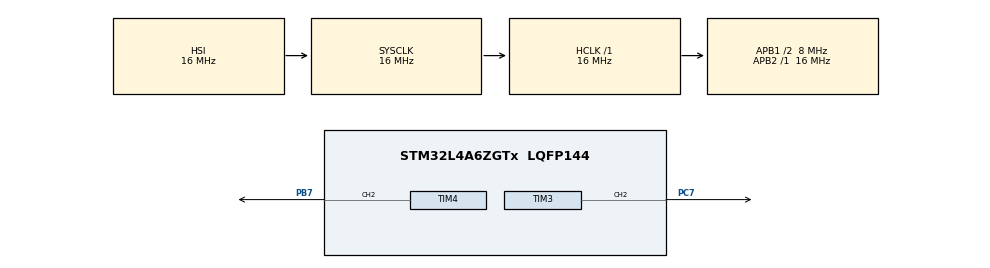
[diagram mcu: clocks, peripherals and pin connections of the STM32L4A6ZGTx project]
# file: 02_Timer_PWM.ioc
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Mcu.Family=STM32L4
Mcu.Name=STM32L4A6ZGTx
Mcu.Package=LQFP144
NVIC.PriorityGroup=NVIC_PRIORITYGROUP_4
PB7.Signal=S_TIM4_CH2
PC7.Signal=S_TIM3_CH2
ProjectManager.HeapSize=0x200
ProjectManager.StackSize=0x400
ProjectManager.TargetToolchain=STM32CubeIDE
RCC.ADCFreq_Value=64000000
RCC.AHBFreq_Value=16000000
RCC.APB1CLKDivider=RCC_HCLK_DIV2
RCC.APB1Freq_Value=8000000
RCC.APB1TimFreq_Value=16000000
RCC.APB2Freq_Value=16000000
RCC.APB2TimFreq_Value=16000000
RCC.CortexFreq_Value=16000000
RCC.HCLKFreq_Value=16000000
RCC.HSE_VALUE=8000000
RCC.HSI48_VALUE=48000000
RCC.HSI_VALUE=16000000
RCC.LSE_VALUE=32768
RCC.MSI_VALUE=4000000
RCC.PLLN=10
RCC.PLLSourceVirtual=RCC_PLLSOURCE_HSI
RCC.SYSCLKFreq_VALUE=16000000
RCC.SYSCLKSource=RCC_SYSCLKSOURCE_HSI
RCC.USBFreq_Value=64000000
RCC.VCOOutputFreq_Value=160000000
SH.S_TIM3_CH2.0=TIM3_CH2,PWM Generation2 CH2
SH.S_TIM4_CH2.0=TIM4_CH2,PWM Generation2 CH2
TIM3.Channel-PWM\ Generation2\ CH2=TIM_CHANNEL_2
TIM3.Period=100-1
TIM3.Prescaler=0
TIM4.Channel-PWM\ Generation2\ CH2=TIM_CHANNEL_2
TIM4.Period=100-1
TIM4.Prescaler=16-1
VP_TIM3_VS_ClockSourceINT.Mode=Internal
VP_TIM4_VS_ClockSourceINT.Mode=Internal
board=NUCLEO-L4A6ZG

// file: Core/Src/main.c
/* USER CODE BEGIN Header */
/**
  ******************************************************************************
  * @file           : main.c
  * @brief          : Main program body
  ******************************************************************************
  * @attention
  *
  * Copyright (c) 2024 STMicroelectronics.
  * All rights reserved.
  *
  * This software is licensed under terms that can be found in the LICENSE file
  * in the root directory of this software component.
  * If no LICENSE file comes with this software, it is provided AS-IS.
  *
  ******************************************************************************
  */
/* USER CODE END Header */
#include "main.h"

/* USER CODE BEGIN PM */
#define MAX_PERIOD 100		//Maximum duty cycle
#define MIN_PERIOD 0		//minimum duty cycle
#define PWM_DELAY 15		//small delay in few milliseconds
/* USER CODE END PM */

TIM_HandleTypeDef htim3;
TIM_HandleTypeDef htim4;

/* USER CODE BEGIN PV */
uint8_t pwm_cplt = 1;	// PWM complete flag
int i = MIN_PERIOD;		// Initial duty cycle for LED1
int j = MAX_PERIOD;		// Initial duty cycle for LED2
/* USER CODE END PV */

void SystemClock_Config(void);
static void MX_GPIO_Init(void);
static void MX_TIM4_Init(void);
static void MX_TIM3_Init(void);

int main(void)
{

  /* MCU Configuration--------------------------------------------------------*/

  /* Reset of all peripherals, Initializes the Flash interface and the Systick. */
  HAL_Init();

  /* Configure the system clock */
  SystemClock_Config();

  /* Initialize all configured peripherals */
  MX_GPIO_Init();
  MX_TIM4_Init();
  MX_TIM3_Init();
  /* USER CODE BEGIN 2 */

  HAL_TIM_PWM_Start(&htim4, TIM_CHANNEL_2);
  HAL_TIM_PWM_Start(&htim3, TIM_CHANNEL_2);

  /* USER CODE END 2 */

  /* Infinite loop */
  while (1)
  {

    /* USER CODE BEGIN 3 */

	  if(pwm_cplt == 1)
	  {
		  if((i<MAX_PERIOD) && (j>MIN_PERIOD))
		  {
			  // Set PWM duty cycle for LED1
			  __HAL_TIM_SET_COMPARE(&htim4, TIM_CHANNEL_2, i);
			  // Set PWM duty cycle for LED2
			  __HAL_TIM_SET_COMPARE(&htim3, TIM_CHANNEL_2, j);
			  i++;		// Increase duty cycle for LED1
			  j--;		// Decrease duty cycle for LED2
			  HAL_Delay(PWM_DELAY);		// Delay to create visible transition
		  }
		  else if(i==MAX_PERIOD && j==MIN_PERIOD)
		  {
			  pwm_cplt  = 0;		// Reset flag to reverse the process
		  }
	  }
	  else
	  {
		  if((i>MIN_PERIOD) && (j<100))
		  {
			  // Set PWM duty cycle for LED1
			  __HAL_TIM_SET_COMPARE(&htim4, TIM_CHANNEL_2, i);
			  // Set PWM duty cycle for LED2
			  __HAL_TIM_SET_COMPARE(&htim3, TIM_CHANNEL_2, j);
			  i--;		// Decrease duty cycle for LED1
			  j++;		// Increase duty cycle for LED2
			  HAL_Delay(PWM_DELAY);		// Delay to create visible transition
		  }
		  else if(i == MIN_PERIOD && j == MAX_PERIOD)
		  {
			  pwm_cplt = 1;			// Reset flag to reverse the process
		  }
	  }

  }
  /* USER CODE END 3 */
}

void SystemClock_Config(void)
{
  RCC_OscInitTypeDef RCC_OscInitStruct = {0};
  RCC_ClkInitTypeDef RCC_ClkInitStruct = {0};

  /** Configure the main internal regulator output voltage
  */
  if (HAL_PWREx_ControlVoltageScaling(PWR_REGULATOR_VOLTAGE_SCALE1) != HAL_OK)
  {
    Error_Handler();
  }

  /** Initializes the RCC Oscillators according to the specified parameters
  * in the RCC_OscInitTypeDef structure.
  */
  RCC_OscInitStruct.OscillatorType = RCC_OSCILLATORTYPE_HSI;
  RCC_OscInitStruct.HSIState = RCC_HSI_ON;
  RCC_OscInitStruct.HSICalibrationValue = RCC_HSICALIBRATION_DEFAULT;
  RCC_OscInitStruct.PLL.PLLState = RCC_PLL_NONE;
  if (HAL_RCC_OscConfig(&RCC_OscInitStruct) != HAL_OK)
  {
    Error_Handler();
  }

  /** Initializes the CPU, AHB and APB buses clocks
  */
  RCC_ClkInitStruct.ClockType = RCC_CLOCKTYPE_HCLK|RCC_CLOCKTYPE_SYSCLK
                              |RCC_CLOCKTYPE_PCLK1|RCC_CLOCKTYPE_PCLK2;
  RCC_ClkInitStruct.SYSCLKSource = RCC_SYSCLKSOURCE_HSI;
  RCC_ClkInitStruct.AHBCLKDivider = RCC_SYSCLK_DIV1;
  RCC_ClkInitStruct.APB1CLKDivider = RCC_HCLK_DIV2;
  RCC_ClkInitStruct.APB2CLKDivider = RCC_HCLK_DIV1;

  if (HAL_RCC_ClockConfig(&RCC_ClkInitStruct, FLASH_LATENCY_0) != HAL_OK)
  {
    Error_Handler();
  }
}

static void MX_TIM3_Init(void)
{

  TIM_ClockConfigTypeDef sClockSourceConfig = {0};
  TIM_MasterConfigTypeDef sMasterConfig = {0};
  TIM_OC_InitTypeDef sConfigOC = {0};

  htim3.Instance = TIM3;
  htim3.Init.Prescaler = 16-1;
  htim3.Init.CounterMode = TIM_COUNTERMODE_UP;
  htim3.Init.Period = 100-1;
  htim3.Init.ClockDivision = TIM_CLOCKDIVISION_DIV1;
  htim3.Init.AutoReloadPreload = TIM_AUTORELOAD_PRELOAD_DISABLE;
  if (HAL_TIM_Base_Init(&htim3) != HAL_OK)
  {
    Error_Handler();
  }
  sClockSourceConfig.ClockSource = TIM_CLOCKSOURCE_INTERNAL;
  if (HAL_TIM_ConfigClockSource(&htim3, &sClockSourceConfig) != HAL_OK)
  {
    Error_Handler();
  }
  if (HAL_TIM_PWM_Init(&htim3) != HAL_OK)
  {
    Error_Handler();
  }
  sMasterConfig.MasterOutputTrigger = TIM_TRGO_RESET;
  sMasterConfig.MasterSlaveMode = TIM_MASTERSLAVEMODE_DISABLE;
  if (HAL_TIMEx_MasterConfigSynchronization(&htim3, &sMasterConfig) != HAL_OK)
  {
    Error_Handler();
  }
  sConfigOC.OCMode = TIM_OCMODE_PWM1;
  sConfigOC.Pulse = 0;
  sConfigOC.OCPolarity = TIM_OCPOLARITY_HIGH;
  sConfigOC.OCFastMode = TIM_OCFAST_DISABLE;
  if (HAL_TIM_PWM_ConfigChannel(&htim3, &sConfigOC, TIM_CHANNEL_2) != HAL_OK)
  {
    Error_Handler();
  }
  HAL_TIM_MspPostInit(&htim3);

}

static void MX_TIM4_Init(void)
{

  TIM_ClockConfigTypeDef sClockSourceConfig = {0};
  TIM_MasterConfigTypeDef sMasterConfig = {0};
  TIM_OC_InitTypeDef sConfigOC = {0};

  htim4.Instance = TIM4;
  htim4.Init.Prescaler = 16-1;
  htim4.Init.CounterMode = TIM_COUNTERMODE_UP;
  htim4.Init.Period = 100-1;
  htim4.Init.ClockDivision = TIM_CLOCKDIVISION_DIV1;
  htim4.Init.AutoReloadPreload = TIM_AUTORELOAD_PRELOAD_DISABLE;
  if (HAL_TIM_Base_Init(&htim4) != HAL_OK)
  {
    Error_Handler();
  }
  sClockSourceConfig.ClockSource = TIM_CLOCKSOURCE_INTERNAL;
  if (HAL_TIM_ConfigClockSource(&htim4, &sClockSourceConfig) != HAL_OK)
  {
    Error_Handler();
  }
  if (HAL_TIM_PWM_Init(&htim4) != HAL_OK)
  {
    Error_Handler();
  }
  sMasterConfig.MasterOutputTrigger = TIM_TRGO_RESET;
  sMasterConfig.MasterSlaveMode = TIM_MASTERSLAVEMODE_DISABLE;
  if (HAL_TIMEx_MasterConfigSynchronization(&htim4, &sMasterConfig) != HAL_OK)
  {
    Error_Handler();
  }
  sConfigOC.OCMode = TIM_OCMODE_PWM1;
  sConfigOC.Pulse = 0;
  sConfigOC.OCPolarity = TIM_OCPOLARITY_HIGH;
  sConfigOC.OCFastMode = TIM_OCFAST_DISABLE;
  if (HAL_TIM_PWM_ConfigChannel(&htim4, &sConfigOC, TIM_CHANNEL_2) != HAL_OK)
  {
    Error_Handler();
  }
  HAL_TIM_MspPostInit(&htim4);

}

static void MX_GPIO_Init(void)
{

  /* GPIO Ports Clock Enable */
  __HAL_RCC_GPIOC_CLK_ENABLE();
  __HAL_RCC_GPIOB_CLK_ENABLE();

}

void Error_Handler(void)
{
  __disable_irq();
  while (1)
  {
  }
}
